AUTOSAR XML (schema 00049)
package /Application/DltConfig
  dlt log channel to process mapping DltLogChannelToProcessMapping_SOA_MoodLamp_TO_SOA_MoodLamp: dlt-log-channel=SOA_MoodLamp, process=SOA_MoodLamp
package /Application/Executable
  executable SOA_MoodLamp: category=APPLICATION_LEVEL, logging-behavior=USES-LOGGING, reporting-behavior=REPORTS-EXECUTION-STATE, version=1.0.0
    root sw component prototype AA: application-type=SOA_MoodLamp
package /Application/Manifest
  service instance to port prototype mapping SOA_MoodLamp_AA_PPort_SOA_MoodLamp: port-prototype=AA.PPort_SOA_MoodLamp, process=SOA_MoodLamp, service-instance=Provider_SoaMlm
  service instance to port prototype mapping SOA_MoodLamp_AA_RPort_Zone1Mlm: port-prototype=AA.RPort_Zone1Mlm, process=SOA_MoodLamp, service-instance=Consumer_Zone1Mlm
  service instance to port prototype mapping SOA_MoodLamp_AA_RPort_Zone1VehicleInfo: port-prototype=AA.RPort_Zone1VehicleInfo, process=SOA_MoodLamp, service-instance=Consumer_SoaMoodlamp_VehicleInfo
package /Application/Package/SOA_MoodLamp/SoftwareCluster_1_0_0
  software cluster SOA_MoodLamp_SoftwareCluster: category=APPLICATION_LAYER, contained-ar-element=SOA_MoodLamp, contained-package-element=[SOA_MoodLamp_AA_PPort_SOA_MoodLamp, SOA_MoodLamp_AA_RPort_Zone1Mlm], contained-process=SOA_MoodLamp, vendor-id=79, vendor-signature=ParaCertificate, version=1.0.0
package /Application/Package/SOA_MoodLamp/SoftwareCluster_1_0_1
  software cluster SOA_MoodLamp_SoftwareCluster: category=APPLICATION_LAYER, contained-ar-element=SOA_MoodLamp, contained-package-element=[SOA_MoodLamp_AA_PPort_SOA_MoodLamp, SOA_MoodLamp_AA_RPort_Zone1Mlm], contained-process=SOA_MoodLamp, vendor-id=79, vendor-signature=ParaCertificate, version=1.0.1
package /Application/Package/SOA_MoodLamp/SoftwareCluster_1_0_2
  software cluster SOA_MoodLamp_SoftwareCluster: category=APPLICATION_LAYER, contained-ar-element=SOA_MoodLamp, contained-package-element=[SOA_MoodLamp_AA_PPort_SOA_MoodLamp, SOA_MoodLamp_AA_RPort_Zone1Mlm], contained-process=SOA_MoodLamp, vendor-id=79, vendor-signature=ParaCertificate, version=1.0.2
package /Application/Package/SOA_MoodLamp/SoftwarePackage
  software package SOA_MoodLamp_InstallSoftwarePackage_1_0_0: action-type=INSTALL, compressed-software-package-size=0, maximum-supported-ucm-version=1.0.0, minimum-supported-ucm-version=1.0.0, packager-id=79, packager-signature=ParaCertificate, post-verification-reboot=false, pre-activate=SC.Off, pre-activation-reboot=false, software-cluster=SoftwareCluster_1_0_0/SOA_MoodLamp_SoftwareCluster, uncompressed-software-cluster-size=0, verify=SC.Verify
  software package SOA_MoodLamp_RemoveSoftwarePackage_1_0_2: action-type=REMOVE, compressed-software-package-size=0, maximum-supported-ucm-version=1.0.0, minimum-supported-ucm-version=1.0.0, packager-id=79, packager-signature=ParaCertificate, post-verification-reboot=false, pre-activate=SC.Off, pre-activation-reboot=false, software-cluster=SoftwareCluster_1_0_2/SOA_MoodLamp_SoftwareCluster, uncompressed-software-cluster-size=0, verify=SC.Verify
  software package SOA_MoodLamp_UpdateSoftwarePackage_1_0_1: action-type=UPDATE, compressed-software-package-size=0, maximum-supported-ucm-version=1.0.0, minimum-supported-ucm-version=1.0.0, packager-id=79, packager-signature=ParaCertificate, post-verification-reboot=false, pre-activate=SC.Off, pre-activation-reboot=false, software-cluster=SoftwareCluster_1_0_1/SOA_MoodLamp_SoftwareCluster, uncompressed-software-cluster-size=0, verify=SC.Verify
package /Application/Package/SOA_MoodLamp/VehiclePackage
  vehicle package SOA_MoodLamp_InstallVehiclePackage_1_0_0: vehicle-driver-notification{approval-required=true, notification-state=PROCESS}, packager-signature=ParaCertificate
    rollout-qualifications:
      vehicle rollout step RolloutQualification0
        ucm-processings:
          ucm step UcmProcessing0: ucm=SOA_MoodLamp_InstallVehiclePackage_1_0_0/EEVP_UCM
            software package step SoftwarePackageStep0: process=SOA_MoodLamp_InstallSoftwarePackage_1_0_0, transfers=software-package-storing={storing=UCM, transfer=SOA_MoodLamp_InstallSoftwarePackage_1_0_0}
    ucm description EEVP_UCM: identifier=EEVP_UCM
  vehicle package SOA_MoodLamp_RemoveVehiclePackage_1_0_2: vehicle-driver-notification{approval-required=true, notification-state=PROCESS}, packager-signature=ParaCertificate
    rollout-qualifications:
      vehicle rollout step RolloutQualification0
        ucm-processings:
          ucm step UcmProcessing0: ucm=SOA_MoodLamp_RemoveVehiclePackage_1_0_2/EEVP_UCM
            software package step SoftwarePackageStep0: process=SOA_MoodLamp_RemoveSoftwarePackage_1_0_2, transfers=software-package-storing={storing=UCM, transfer=SOA_MoodLamp_RemoveSoftwarePackage_1_0_2}
    ucm description EEVP_UCM: identifier=EEVP_UCM
  vehicle package SOA_MoodLamp_UpdateVehiclePackage_1_0_1: vehicle-driver-notification{approval-required=true, notification-state=PROCESS}, packager-signature=ParaCertificate
    rollout-qualifications:
      vehicle rollout step RolloutQualification0
        ucm-processings:
          ucm step UcmProcessing0: ucm=SOA_MoodLamp_UpdateVehiclePackage_1_0_1/EEVP_UCM
            software package step SoftwarePackageStep0: process=SOA_MoodLamp_UpdateSoftwarePackage_1_0_1, transfers=software-package-storing={storing=UCM, transfer=SOA_MoodLamp_UpdateSoftwarePackage_1_0_1}
    ucm description EEVP_UCM: identifier=EEVP_UCM
package /Application/Process
  process SOA_MoodLamp: executable=SOA_MoodLamp, state-dependent-startup-config{function-group-state=[SC.On, SC.Verify], resource-group=DefaultResourceGroup, startup-config=SOA}
    process state machine SOA_MoodLamp: type=ProcessState
package /Application/SwComponent
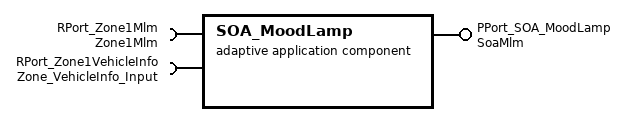
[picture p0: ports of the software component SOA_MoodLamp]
  adaptive application sw component type SOA_MoodLamp
    provide port PPort_SOA_MoodLamp: provided-interface=SoaMlm
    require port RPort_Zone1Mlm: required-interface=Zone1Mlm
    require port RPort_Zone1VehicleInfo: required-interface=Zone_VehicleInfo_Input
